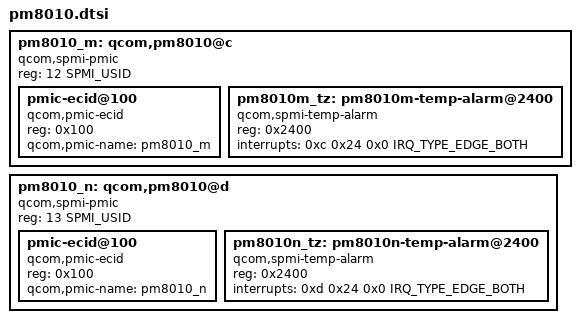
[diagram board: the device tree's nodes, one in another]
// SPDX-License-Identifier: BSD-3-Clause
/*
 * Copyright (c) 2022-2025 Qualcomm Innovation Center, Inc. All rights reserved.
 */

#include <dt-bindings/interrupt-controller/irq.h>
#include <dt-bindings/spmi/spmi.h>

pm8010_m: qcom,pm8010@c {
	compatible = "qcom,spmi-pmic";
	reg = <12 SPMI_USID>;
	#address-cells = <1>;
	#size-cells = <0>;

	pmic-ecid@100 {
		compatible = "qcom,pmic-ecid";
		reg = <0x100>;
		qcom,pmic-name = "pm8010_m";
	};

	pm8010m_tz: pm8010m-temp-alarm@2400 {
		compatible = "qcom,spmi-temp-alarm";
		reg = <0x2400>;
		interrupts = <0xc 0x24 0x0 IRQ_TYPE_EDGE_BOTH>;
		#thermal-sensor-cells = <0>;
	};
};

pm8010_n: qcom,pm8010@d {
	compatible = "qcom,spmi-pmic";
	reg = <13 SPMI_USID>;
	#address-cells = <1>;
	#size-cells = <0>;

	pmic-ecid@100 {
		compatible = "qcom,pmic-ecid";
		reg = <0x100>;
		qcom,pmic-name = "pm8010_n";
	};

	pm8010n_tz: pm8010n-temp-alarm@2400 {
		compatible = "qcom,spmi-temp-alarm";
		reg = <0x2400>;
		interrupts = <0xd 0x24 0x0 IRQ_TYPE_EDGE_BOTH>;
		#thermal-sensor-cells = <0>;
	};
};
